# CY8C5888LTI_LP097 register map
File version: 0.1
CY8C58LP
Registers are 8-bit, read-write, no defined reset value unless marked. A register's access mark holds for its fields unless they carry their own. Offsets are from the block's base; lines under a group give offsets from that group; [hi:lo] are bit positions; {n}, {i} and the like mark numbered series; 'fields as' and 'values as' point back to an identical list; <NAME> marks a mode.

## Memory map
0x00000000 SEQUENCER_CONTROL
0x00000000 OUTPUT_VOLTAGE_ADC — SAR ADC
0x00000000 INPUT_VOLTAGE_ADC — SAR ADC
0x00000000 DRIVESELECT_REG
0x00000000 TK43_REG
0x00000000 INDEX_REG
0x00000000 SAMPLER_CONTROL
0x00000000 DENSITY_REG
0x00000000 FAKE_INDEX_GENERATOR_REG
0x00000000 MOTOR_REG
0x00000000 TRACK0_REG
0x00000000 USBFS
0x00000000 DISKSTATUS_REG
0x00000000 ERASE_REG
0x00000000 STEP_REG
0x00000000 SIDE_REG

## SEQUENCER_CONTROL
Base 0x00000000
0x40006575 SEQUENCER_CONTROL_CONTROL_REG

## OUTPUT_VOLTAGE_ADC — SAR ADC
Base 0x00000000
0x40004616 SAR_TR0 — SAR trim register
{0x40005908+i} SAR_CSR{i} (i=0..6) — SAR status and control register {i}
0x40005B28 SAR_SW0 — SAR Analog Routing Register 0
{0x40005B28+i} SAR_SW{i} (i=2..4) — SAR Analog Routing Register {i}
0x40005B2E SAR_SW6 — SAR Analog Routing Register 6
0x40005B2F SAR_CLK — SAR Clock Selection Register
0x40005BA2 SAR_WRK 16-bit — SAR working register

## INPUT_VOLTAGE_ADC — SAR ADC
Base 0x00000000
0x40004614 SAR_TR0 — SAR trim register
{0x40005900+i} SAR_CSR{i} (i=0..6) — SAR status and control register {i}
0x40005B20 SAR_SW0 — SAR Analog Routing Register 0
{0x40005B20+i} SAR_SW{i} (i=2..4) — SAR Analog Routing Register {i}
0x40005B26 SAR_SW6 — SAR Analog Routing Register 6
0x40005B27 SAR_CLK — SAR Clock Selection Register
0x40005BA0 SAR_WRK 16-bit — SAR working register

## DRIVESELECT_REG
Base 0x00000000
0x40006478 DRIVESELECT_REG_CONTROL_REG

## TK43_REG
Base 0x00000000
0x40006479 TK43_REG_CONTROL_REG

## INDEX_REG
Base 0x00000000
0x40006475 INDEX_REG_CONTROL_REG

## SAMPLER_CONTROL
Base 0x00000000
0x40006473 SAMPLER_CONTROL_CONTROL_REG

## DENSITY_REG
Base 0x00000000
0x40006472 DENSITY_REG_CONTROL_REG

## FAKE_INDEX_GENERATOR_REG
Base 0x00000000
0x40006476 FAKE_INDEX_GENERATOR_REG_CONTROL_REG

## MOTOR_REG
Base 0x00000000
0x40006576 MOTOR_REG_CONTROL_REG

## TRACK0_REG
Base 0x00000000
0x40006467 TRACK0_REG_STATUS_REG
0x40006487 TRACK0_REG_MASK_REG
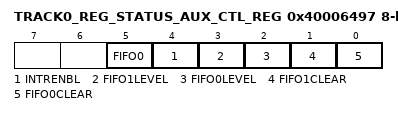
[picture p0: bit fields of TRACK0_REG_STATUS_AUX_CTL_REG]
0x40006497 TRACK0_REG_STATUS_AUX_CTL_REG
  [5] FIFO0 — FIFO0 clear
    1=ENABLED (Enable counter); 0=DISABLED (Disable counter)
  [4] INTRENBL — Enables or disables the Interrupt
    1=ENABLED (Interrupt enabled); 0=DISABLED (Interrupt disabled)
  [3] FIFO1LEVEL — FIFO level
    1=ENABLED (FIFO LVL: input mode: FIFO at least 1/2 empty; output mode: FIFO at least 1/2 full); 0=DISABLED (FIFO LVL: input mode: FIFO not full; output mode: FIFO not empty)
  [2] FIFO0LEVEL — FIFO level
    values as FIFO1LEVEL
  [1] FIFO1CLEAR — FIFO clear
    1=ENABLED (Clear FIFO state); 0=DISABLED (Normal FIFO operation)
  [0] FIFO0CLEAR — FIFO clear
    values as FIFO1CLEAR

## DISKSTATUS_REG
Base 0x00000000
0x40006469 DISKSTATUS_REG_STATUS_REG
0x40006489 DISKSTATUS_REG_MASK_REG
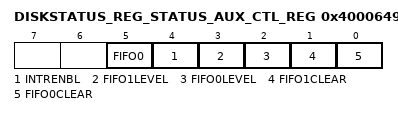
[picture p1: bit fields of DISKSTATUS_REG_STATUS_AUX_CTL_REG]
0x40006499 DISKSTATUS_REG_STATUS_AUX_CTL_REG
  [5] FIFO0 — FIFO0 clear
    1=ENABLED (Enable counter); 0=DISABLED (Disable counter)
  [4] INTRENBL — Enables or disables the Interrupt
    1=ENABLED (Interrupt enabled); 0=DISABLED (Interrupt disabled)
  [3] FIFO1LEVEL — FIFO level
    1=ENABLED (FIFO LVL: input mode: FIFO at least 1/2 empty; output mode: FIFO at least 1/2 full); 0=DISABLED (FIFO LVL: input mode: FIFO not full; output mode: FIFO not empty)
  [2] FIFO0LEVEL — FIFO level
    values as FIFO1LEVEL
  [1] FIFO1CLEAR — FIFO clear
    1=ENABLED (Clear FIFO state); 0=DISABLED (Normal FIFO operation)
  [0] FIFO0CLEAR — FIFO clear
    values as FIFO1CLEAR
